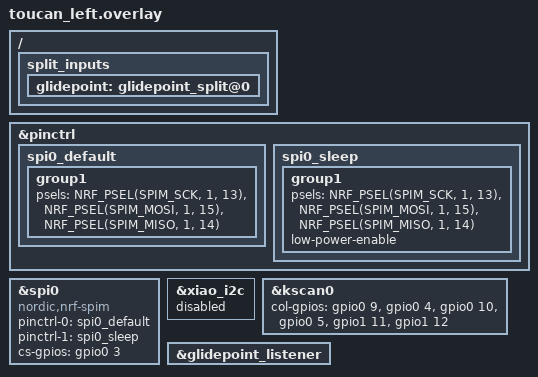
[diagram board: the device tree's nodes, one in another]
#include "toucan.dtsi"

&pinctrl {
    spi0_default: spi0_default {
        group1 {
            psels = <NRF_PSEL(SPIM_SCK, 1, 13)>,
                <NRF_PSEL(SPIM_MOSI, 1, 15)>,
                <NRF_PSEL(SPIM_MISO, 1, 14)>;
        };
    };

     spi0_sleep: spi0_sleep {
        group1 {
            psels = <NRF_PSEL(SPIM_SCK, 1, 13)>,
                    <NRF_PSEL(SPIM_MOSI, 1, 15)>,
                    <NRF_PSEL(SPIM_MISO, 1, 14)>;
            low-power-enable;
        };
    };

};

nice_view_spi: &spi0 {
   compatible = "nordic,nrf-spim";
   pinctrl-0 = <&spi0_default>;
   pinctrl-1 = <&spi0_sleep>;
   pinctrl-names = "default", "sleep";
   cs-gpios = <&gpio0 3 GPIO_ACTIVE_HIGH>;
};

&xiao_i2c {
    status = "disabled";
};

&kscan0 {
    col-gpios
    = <&gpio0 9 GPIO_ACTIVE_HIGH>
    , <&gpio0 4 GPIO_ACTIVE_HIGH>
    , <&gpio0 10 GPIO_ACTIVE_HIGH>
    , <&gpio0 5 GPIO_ACTIVE_HIGH>
    , <&gpio1 11 GPIO_ACTIVE_HIGH>
    , <&gpio1 12 GPIO_ACTIVE_HIGH>
    ;
};

&glidepoint_listener {
    status = "okay";
};

/*
 * The halfdane gesture module hard-codes a reference to
 * DT_NODELABEL(glidepoint) for its pm_device pointer
 * (input_processor_gestures.c line ~103). On this split keyboard the
 * cirque chip — and thus the `glidepoint` label — only exists on the
 * right (peripheral) overlay. The gestures module compiles only on the
 * central (left), so without this re-declaration the build fails with
 * `__device_dts_ord_DT_N_NODELABEL_glidepoint_ORD undeclared`.
 *
 * Re-declaring `/split_inputs/glidepoint_split@0` here adds a second
 * label (`glidepoint`) to the existing input-split node, so the module
 * can resolve a device pointer. The pm pointer is stored in
 * dev->pm but never dereferenced at runtime by the gesture code, so
 * pointing it at the input-split is harmless.
 */
/ {
    split_inputs {
        glidepoint: glidepoint_split@0 {
        };
    };
};
